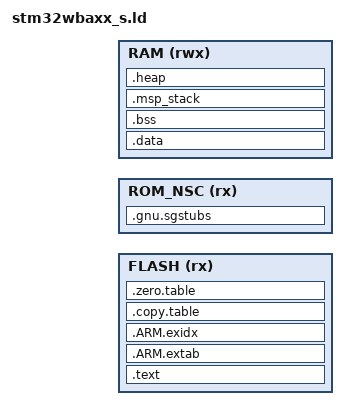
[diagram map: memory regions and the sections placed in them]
/*
******************************************************************************
**
** @file        : LinkerScript.ld
**
** @author      : Auto-generated by STM32CubeIDE
**
** @brief       : Linker script for STM32WBAxx Device from STM32WBA series
**
**                Set heap size, stack size and stack location according
**                to application requirements.
**
**                Set memory bank area and size if external memory is used
**
**  Target      : STMicroelectronics STM32
**
**  Distribution: The file is distributed as is, without any warranty
**                of any kind.
**
******************************************************************************
** @attention
**
** Copyright (c) 2024 STMicroelectronics.
** All rights reserved.
**
** This software is licensed under terms that can be found in the LICENSE file
** in the root directory of this software component.
** If no LICENSE file comes with this software, it is provided AS-IS.
**
******************************************************************************
*/
/*************************************************************************************************/
#include "loader_region_defs.h"
/*************************************************************************************************/

#include "loader_region_defs.h"

MEMORY
{
  FLASH (rx)  : ORIGIN = LOADER_S_CODE_START, LENGTH = LOADER_S_CODE_SIZE
  ROM_NSC (rx): ORIGIN = NSC_LOADER_START, LENGTH = NSC_LOADER_SIZE
  RAM   (rwx) : ORIGIN = LOADER_S_DATA_START, LENGTH = LOADER_S_DATA_SIZE
}

__heap_size__  = LOADER_S_HEAP_SIZE;
__msp_stack_size__ = LOADER_S_MSP_STACK_SIZE;

/* Library configurations */
GROUP(libgcc.a libc.a libm.a libnosys.a)

ENTRY(Reset_Handler)

SECTIONS
{
    .text :
    {
        KEEP(*(.vectors))
        __Vectors_End = .;
        __Vectors_Size = __Vectors_End - __Vectors;
        __end__ = .;

        *(.text*)

        KEEP(*(.init))
        KEEP(*(.fini))


        /* .ctors */
        *crtbegin.o(.ctors)
        *crtbegin?.o(.ctors)
        *(EXCLUDE_FILE(*crtend?.o *crtend.o) .ctors)
        *(SORT(.ctors.*))
        *(.ctors)

        /* .dtors */
         *crtbegin.o(.dtors)
         *crtbegin?.o(.dtors)
         *(EXCLUDE_FILE(*crtend?.o *crtend.o) .dtors)
         *(SORT(.dtors.*))
         *(.dtors)

        *(.rodata*)

        KEEP(*(.eh_frame*))
    } > FLASH

    .ARM.extab (READONLY) : /* The READONLY keyword is only supported in GCC11 and later, remove it if using GCC10 or earlier. */
    {
        *(.ARM.extab* .gnu.linkonce.armextab.*)
    } > FLASH

    __exidx_start = .;
    .ARM.exidx (READONLY) : /* The READONLY keyword is only supported in GCC11 and later, remove it if using GCC10 or earlier. */
    {
        *(.ARM.exidx* .gnu.linkonce.armexidx.*)
    } > FLASH
    __exidx_end = .;

    .copy.table (READONLY) : /* The READONLY keyword is only supported in GCC11 and later, remove it if using GCC10 or earlier. */
    {
        . = ALIGN(4);
        __copy_table_start__ = .;
        LONG (__etext)
        LONG (__data_start__)
        LONG ((__data_end__ - __data_start__)/4)
        __copy_table_end__ = .;
    } > FLASH

    /* To clear multiple BSS sections,
     * uncomment .zero.table section and,
     * define __STARTUP_CLEAR_BSS_MULTIPLE  */
    .zero.table (READONLY) : /* The READONLY keyword is only supported in GCC11 and later, remove it if using GCC10 or earlier. */
    {
        . = ALIGN(4);
        __zero_table_start__ = .;
        LONG (__bss_start__)
        LONG ((__bss_end__ - __bss_start__)/4)
        __zero_table_end__ = .;
    } > FLASH

    __etext = .;

    .data (LOADER_S_DATA_START) : AT (__etext)
    {
        __data_start__ = .;
        *(vtable)
        *(.data*)

        . = ALIGN(4);
        /* preinit data */
        PROVIDE_HIDDEN (__preinit_array_start = .);
        KEEP(*(.preinit_array))
        PROVIDE_HIDDEN (__preinit_array_end = .);

        . = ALIGN(4);
        /* init data */
        PROVIDE_HIDDEN (__init_array_start = .);
        KEEP(*(SORT(.init_array.*)))
        KEEP(*(.init_array))
        PROVIDE_HIDDEN (__init_array_end = .);


        . = ALIGN(4);
        /* finit data */
        PROVIDE_HIDDEN (__fini_array_start = .);
        KEEP(*(SORT(.fini_array.*)))
        KEEP(*(.fini_array))
        PROVIDE_HIDDEN (__fini_array_end = .);

        KEEP(*(.jcr*))
        . = ALIGN(4);
        /* All data end */
        __data_end__ = .;

    } > RAM

    .bss :
    {
        . = ALIGN(4);
        __bss_start__ = .;
        *(.bss*)
        *(COMMON)
        . = ALIGN(4);
        __bss_end__ = .;
    } > RAM

    bss_size = __bss_end__ - __bss_start__;

    .msp_stack : ALIGN(32)
    {
        . += __msp_stack_size__;
    } > RAM
    Image$$ARM_LIB_STACK_MSP$$ZI$$Limit = ADDR(.msp_stack) + SIZEOF(.msp_stack);
    Image$$ARM_LIB_STACK_MSP$$ZI$$Base = ADDR(.msp_stack);

    .heap : ALIGN(8)
    {
        __end__ = .;
        PROVIDE(end = .);
        __HeapBase = .;
        . += __heap_size__;
        __HeapLimit = .;
        __heap_limit = .; /* Add for _sbrk */
    } > RAM

    .gnu.sgstubs :
    {
    . = ALIGN(8);
    *(.gnu.sgstubs*)   /* Secure Gateway stubs */
    . = ALIGN(8);
    } >ROM_NSC

    PROVIDE(__stack = Image$$ARM_LIB_STACK_MSP$$ZI$$Limit);
    PROVIDE(__StackTop = Image$$ARM_LIB_STACK_MSP$$ZI$$Limit);
    PROVIDE(__StackLimit = Image$$ARM_LIB_STACK_MSP$$ZI$$Base);
}
